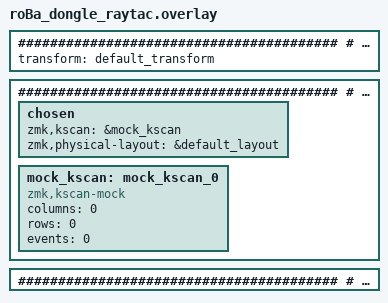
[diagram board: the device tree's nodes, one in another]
#include "roBa.dtsi"
#include "roBa_trackball.dtsi"

########################################
# デフォルトレイアウト設定
########################################
&default_layout {
    transform = <&default_transform>;  /* レイアウト変換を指定 */
};

########################################
# ルートノード設定
########################################
/ {
    chosen {
        zmk,kscan = &mock_kscan;           /* キースキャンにモックを使用 */
        zmk,physical-layout = &default_layout; /* デフォルト物理レイアウトを指定 */
    };

    /* モックキースキャン設定 */
    mock_kscan: mock_kscan_0 {
        compatible = "zmk,kscan-mock";
        columns = <0>;  /* 列数 */
        rows = <0>;     /* 行数 */
        events = <0>;   /* 発火イベント数 */
    };
};

########################################
# トラックボール設定
########################################
&trackball_listener {
    status = "okay";  /* トラックボールを有効化 */
};
